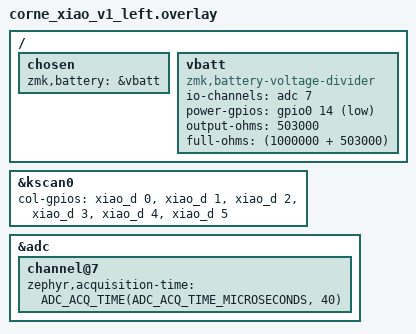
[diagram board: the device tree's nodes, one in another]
#include "corne_xiao_v1.dtsi"

&kscan0 {
    col-gpios
        = <&xiao_d 0 GPIO_ACTIVE_HIGH>
        , <&xiao_d 1 GPIO_ACTIVE_HIGH>
        , <&xiao_d 2 GPIO_ACTIVE_HIGH>
        , <&xiao_d 3 GPIO_ACTIVE_HIGH>
        , <&xiao_d 4 GPIO_ACTIVE_HIGH>
        , <&xiao_d 5 GPIO_ACTIVE_HIGH>
        ;
};

&adc {
    channel@7 {
        zephyr,acquisition-time = <ADC_ACQ_TIME(ADC_ACQ_TIME_MICROSECONDS, 40)>;
    };
};

/ {
    chosen {
        zmk,battery = &vbatt;
    };
    
    vbatt: vbatt {
        compatible = "zmk,battery-voltage-divider";
        io-channels = <&adc 7>;
        power-gpios = <&gpio0 14 (GPIO_OPEN_DRAIN | GPIO_ACTIVE_LOW)>;
        output-ohms = <503000>; // 記事の補正値
        full-ohms = <(1000000 + 503000)>;
    };
};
